# Daric register map
Vendor: Daric; Series: Daric; File version: 1.0
CPU: CM7 r1p2, little endian, MPU, FPU, vendor SysTick, 3 interrupt priority bits
Registers are 32-bit, access not given, reset 0x0 unless marked. A register's access mark holds for its fields unless they carry their own. Offsets are from the block's base; [hi:lo] are bit positions; lines under a group give offsets from that group; {n}, {i} and the like mark numbered series.

## PMU — Power Management Unit & Always-On Domain Control
Base 0x40060000
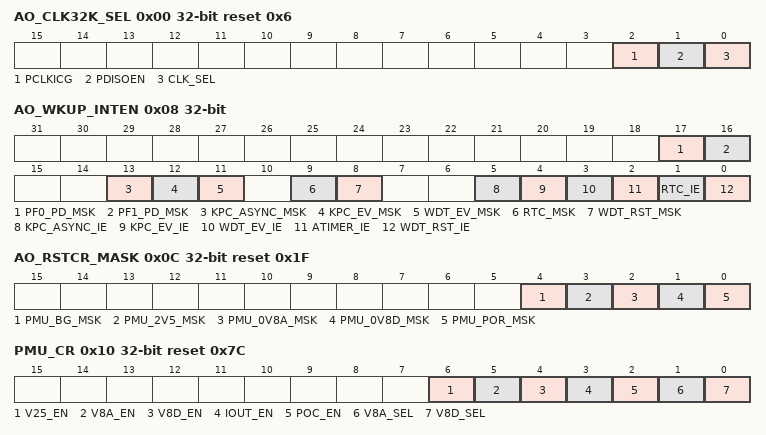
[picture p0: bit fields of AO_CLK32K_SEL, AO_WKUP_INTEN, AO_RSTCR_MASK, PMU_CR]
0x00 AO_CLK32K_SEL reset 0x6 — Always on clock 32KHz source selection
  [2] PCLKICG — PCLK ICG control in power-down
  [1] PDISOEN — Isolation control in power-down
  [0] CLK_SEL — 32k clock source: 0=internal OSC, 1=external XTAL
0x04 AO_CLK1HZ_FD reset 0x3FFF — clk 1Hz frequency division configuration
  [13:0] FD — 1Hz frequency division
0x08 AO_WKUP_INTEN — Wakeup mask and interrupt enable
  [17] PF0_PD_MSK, [16] PF1_PD_MSK, [13] KPC_ASYNC_MSK, [12] KPC_EV_MSK, [11] WDT_EV_MSK, [9] RTC_MSK, [8] WDT_RST_MSK, [5] KPC_ASYNC_IE, [4] KPC_EV_IE, [3] WDT_EV_IE, [2] ATIMER_IE, [1] RTC_IE, [0] WDT_RST_IE
0x0C AO_RSTCR_MASK reset 0x1F — Reset mask control
  [4] PMU_BG_MSK, [3] PMU_2V5_MSK, [2] PMU_0V8A_MSK, [1] PMU_0V8D_MSK, [0] PMU_POR_MSK
0x10 PMU_CR reset 0x7C — PMU control register
  [6] V25_EN
  [5] V8A_EN
  [4] V8D_EN
  [3] IOUT_EN
  [2] POC_EN
  [1] V8A_SEL — 0: 0.8V, 1: 0.95V
  [0] V8D_SEL — 0: 0.8V, 1: 0.95V
0x14 PMU_CRLP — Low Power Control
0x18 PMU_CRPD — Power Down Control
0x1C PMU_DFT — Default Test
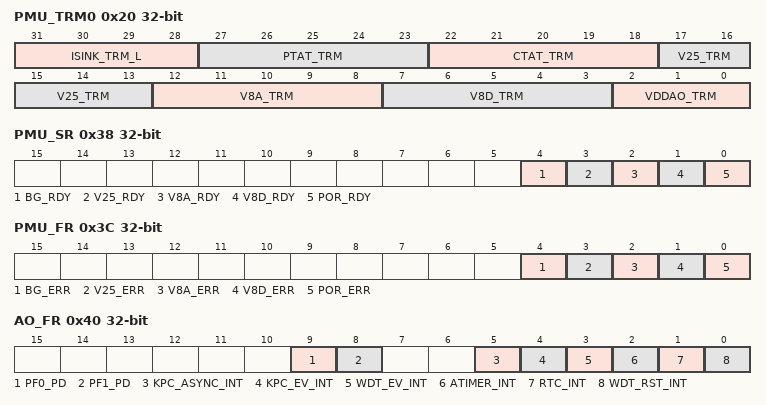
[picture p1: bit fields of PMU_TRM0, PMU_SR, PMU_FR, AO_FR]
0x20 PMU_TRM0 — Trim 0
  [31:28] ISINK_TRM_L, [27:23] PTAT_TRM, [22:18] CTAT_TRM, [17:13] V25_TRM, [12:8] V8A_TRM, [7:3] V8D_TRM, [2:0] VDDAO_TRM
0x24 PMU_TRM1 — Trim 1
  [1:0] ISINK_TRM_H
0x28 PMU_TRMLP0 — Trim Low Power 0
0x2C PMU_TRMLP1 — Trim Low Power 1
0x34 AO_OSC_CR — Always-on 32KHz oscillator IP control
0x38 PMU_SR — Status Register
  [4] BG_RDY, [3] V25_RDY, [2] V8A_RDY, [1] V8D_RDY, [0] POR_RDY
0x3C PMU_FR — Flag Register
  [4] BG_ERR, [3] V25_ERR, [2] V8A_ERR, [1] V8D_ERR, [0] POR_ERR
0x40 AO_FR — AO domain interrupt flag register
  [9] PF0_PD, [8] PF1_PD, [5] KPC_ASYNC_INT, [4] KPC_EV_INT, [3] WDT_EV_INT, [2] ATIMER_INT, [1] RTC_INT, [0] WDT_RST_INT
0x44 PMU_PDAR — Power Down AR
0x50 AO_PERI_CLR — Wake up interrupt clear AR
0x60 AO_IOX — AO IO Pad(Bank F) AF selection
0x64 AO_PADPU — AO IO Pad(Bank F) pull up configuration

## RTC — Real Time Clock
Base 0x40061000
0x00 DR ro — Data register
0x04 MR — Match register
0x08 LR — Load register
0x0C CR — Control register
  [0] START
0x10 IMSC — Interrupt Set or Clear
  [0] IM — Interrupt Mask: 1=Enable
0x14 RIS ro — Raw Interrupt Status
  [0] RIS
0x18 MIS ro — Masked Interrupt Status
  [0] MIS
0x1C ICR wo — Interrupt Clear Register
  [0] ICR

## KPC — Keypad Controller
Base 0x40064000
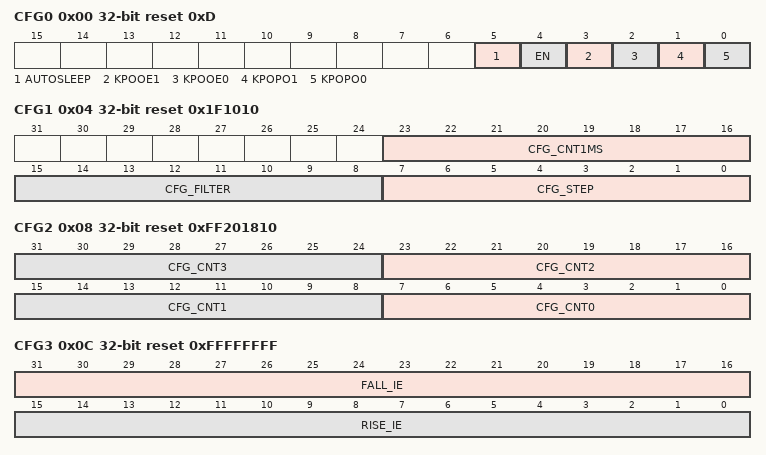
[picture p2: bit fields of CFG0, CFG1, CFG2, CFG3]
0x00 CFG0 reset 0xD — Enable configuration
  [5] AUTOSLEEP, [4] EN, [3] KPOOE1, [2] KPOOE0, [1] KPOPO1, [0] KPOPO0
0x04 CFG1 reset 0x1F1010 — Time configuration
  [23:16] CFG_CNT1MS, [15:8] CFG_FILTER, [7:0] CFG_STEP
0x08 CFG2 reset 0xFF201810 — Sample timing configuration
  [8n+7:8n] CFG_CNT{n} (n=0..3)
0x0C CFG3 reset 0xFFFFFFFF — Node configuration
  [31:16] FALL_IE, [15:0] RISE_IE
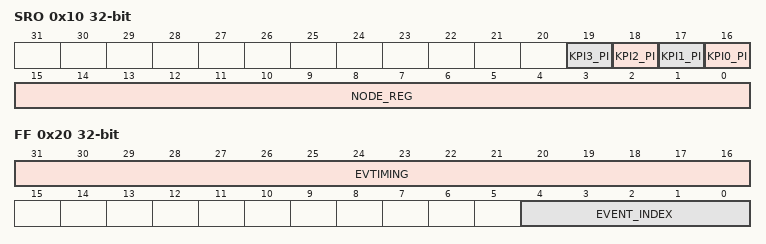
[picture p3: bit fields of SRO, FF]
0x10 SRO ro — Status register 0
  [n+16] KPI{n}_PI (n=0..3), [15:0] NODE_REG
0x14 SR1 ro — Status register 1
  [0] EVENT_FIFO_VALID
0x20 FF — FIFO/Event register
  [31:16] EVTIMING, [4:0] EVENT_INDEX
0x30 CFG4 reset 0x1F4 — Sleep wait time configuration
  [15:0] CFG_DEEP10MS

## QFC — Quad Flash Controller
Base 0x40010000
0x00 IO reset 0xFE
0x04 AR
0x08 IODRV
0x10 XIP_ADDRMODE
0x14 XIP_OPCODE
0x18 XIP_WIDTH
0x1C XIP_SSEL
0x20 XIP_DUMCYCS
0x24 XIP_CFG
0x200 CSR_CTRL reset 0x40
0x204 CSR_CMD_CTRL reset 0x100
0x208 CSR_FIFO_FLUSH
0x20C CSR_FIFO_THRESHOLD
0x210 CSR_FIFO_STATUS reset 0xA8202080
0x214 CSR_CMD_FIFO_STATUS reset 0x2820
0x218 CSR_IRQ_ENABLE
0x21C CSR_IRQ_STATUS
0x230 CSR_TX_FIFO
0x234 CSR_RX_FIFO
0x238 CSR_CMD_FIFO

## PWM — Pulse Width Modulation
Base 0x50120000
{0x0+0x40*i} TIMER[{i}] (i=0..3) group
  0x00 CMD
  0x04 CONFIG
  0x08 THRESHOLD
  {0xC+4j} TH_CHANNEL[{j}] (j=0..3)
  0x2C COUNTER ro
0x100 EVENT_CFG
0x104 CG
{0x140+4i} PREFD[{i}] (i=0..3)

## USB — USB Controller
Base 0x50202400
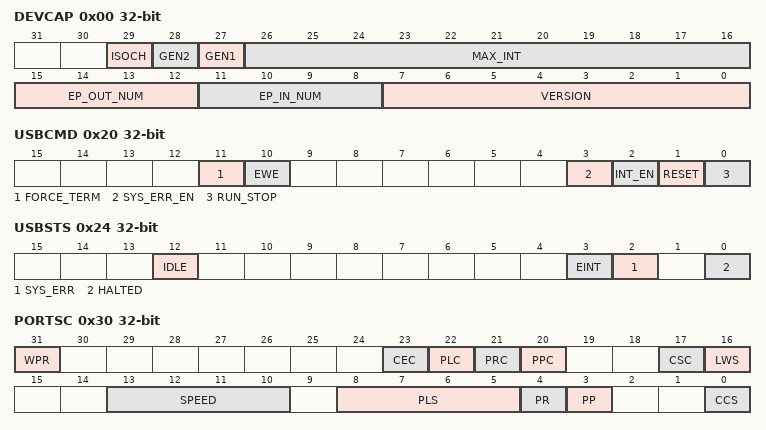
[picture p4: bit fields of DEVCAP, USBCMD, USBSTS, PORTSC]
0x00 DEVCAP ro — Device Capability
  [29] ISOCH — Isoch Support
  [28] GEN2 — Gen2 Support
  [27] GEN1 — Gen1 Support
  [26:16] MAX_INT — Max Interrupts
  [15:12] EP_OUT_NUM — Number of Physical EP OUT
  [11:8] EP_IN_NUM — Number of Physical EP IN
  [7:0] VERSION — Version of Programming Interface
0x10 DEVCONFIG
0x14 EVENTCONFIG
0x20 USBCMD — USB Command
  [11] FORCE_TERM — Force Termination
  [10] EWE — Enable MFINDEX Wrap Event
  [3] SYS_ERR_EN — System Error Enable
  [2] INT_EN — Interrupt Enable
  [1] RESET — Soft Reset
  [0] RUN_STOP
0x24 USBSTS — USB Status
  [12] IDLE — Controller Idle
  [3] EINT — Event Interrupt
  [2] SYS_ERR — System Error
  [0] HALTED — Controller Halted
0x28 DCBAPLO
0x2C DCBAPHI
0x30 PORTSC — Port Status and Control
  [31] WPR — Warm Port Reset
  [23] CEC — Config Error Change
  [22] PLC — Port Link State Change
  [21] PRC — Port Reset Change
  [20] PPC — Port Power Change
  [17] CSC — Connect Status Change
  [16] LWS — Link Write Strobe
  [13:10] SPEED — Port Speed
  [8:5] PLS — Port Link State
  [4] PR — Port Reset
  [3] PP — Power Present
  [0] CCS — Current Connection Status
0x40 DOORBELL
0x60 EPENABLE
0x64 EPRUNNING ro
0x70 CMDPARA0
0x74 CMDPARA1
0x78 CMDCTRL
{0x100+0x20*i} IMAN[{i}] (i=0..3)
{0x104+0x20*i} IMOD[{i}] (i=0..3)
0x108 ERSTSZ
0x110 ERSTBALO
0x114 ERSTBAHI
0x118 ERDPLO
0x11C ERDPHI
